VERSION ""

NS_ :

BS_:

BU_: VCU ACU Jetson Maxon Dynamics FSG_Datalogger RES

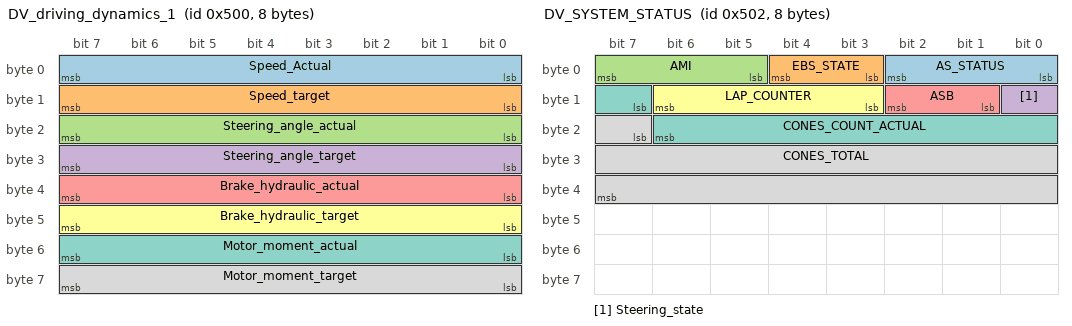
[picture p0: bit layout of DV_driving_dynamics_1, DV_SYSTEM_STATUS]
BO_ 1280 DV_driving_dynamics_1: 8 Dynamics
 SG_ Speed_Actual : 0|8@1+ (1,0) [0|0] "Km/h"  FSG_Datalogger
 SG_ Speed_target : 8|8@1+ (1,0) [0|0] "Km/h"  FSG_Datalogger
 SG_ Steering_angle_actual : 16|8@1- (1,0) [0|0] "°"  FSG_Datalogger
 SG_ Steering_angle_target : 24|8@1- (1,0) [0|0] "°"  FSG_Datalogger
 SG_ Brake_hydraulic_actual : 32|8@1+ (1,0) [0|0] "%"  FSG_Datalogger,ACU
 SG_ Brake_hydraulic_target : 40|8@1+ (1,0) [0|0] "%"  FSG_Datalogger
 SG_ Motor_moment_actual : 48|8@1- (1,0) [0|0] "%"  FSG_Datalogger
 SG_ Motor_moment_target : 56|8@1- (1,0) [0|0] "%"  FSG_Datalogger

BO_ 1282 DV_SYSTEM_STATUS: 8 ACU
 SG_ AS_STATUS : 0|3@1+ (1,0) [0|0] ""  FSG_Datalogger
 SG_ EBS_STATE : 3|2@1+ (1,0) [0|0] ""  FSG_Datalogger
 SG_ AMI : 5|3@1+ (1,0) [0|0] ""  FSG_Datalogger
 SG_ Steering_state : 8|1@1+ (1,0) [0|0] ""  FSG_Datalogger
 SG_ ASB : 9|2@1+ (1,0) [0|0] ""  FSG_Datalogger
 SG_ LAP_COUNTER : 11|4@1+ (1,0) [0|0] ""  FSG_Datalogger
 SG_ CONES_COUNT_ACTUAL : 15|8@1+ (1,0) [0|0] ""  FSG_Datalogger
 SG_ CONES_TOTAL : 23|17@1+ (1,0) [0|0] ""  FSG_Datalogger

BO_ 401 RES: 8 RES
 SG_ RES : 0|8@1+ (1,0) [0|0] ""  ACU,Jetson

BO_ 81 ACU_SIGNALS: 2 ACU
 SG_ MS : 0|8@1+ (1,0) [0|0] ""  Jetson
 SG_ IGN : 8|8@1+ (1,0) [0|0] ""  VCU

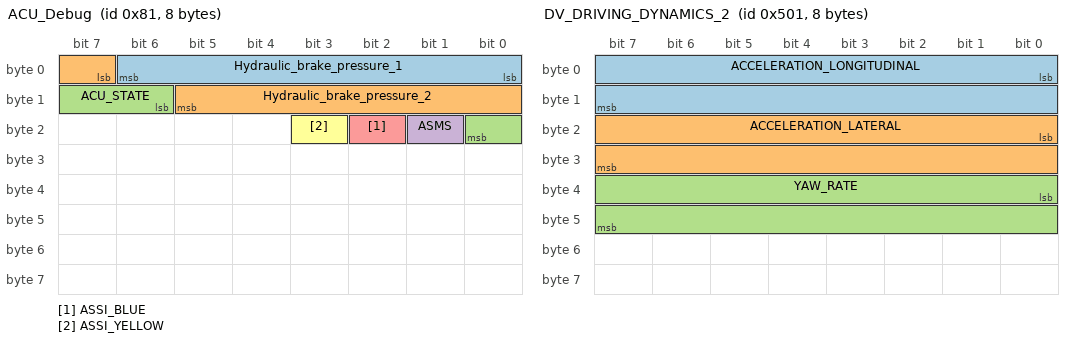
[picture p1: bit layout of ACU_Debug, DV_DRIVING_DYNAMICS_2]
BO_ 129 ACU_Debug: 8 ACU
 SG_ Hydraulic_brake_pressure_1 : 0|7@1+ (0.1,0) [0|10.5] "BAR" Vector__XXX
 SG_ Hydraulic_brake_pressure_2 : 7|7@1+ (0.1,0) [0|10] "BAR" Vector__XXX
 SG_ ACU_STATE : 14|3@1+ (1,0) [0|0] "" Vector__XXX
 SG_ ASMS : 17|1@1+ (1,0) [0|0] "" Vector__XXX
 SG_ ASSI_BLUE : 18|1@1+ (1,0) [0|0] "" Vector__XXX
 SG_ ASSI_YELLOW : 19|1@1+ (1,0) [0|0] "" Vector__XXX

BO_ 1281 DV_DRIVING_DYNAMICS_2: 8 Jetson
 SG_ ACCELERATION_LONGITUDINAL : 0|16@1- (1,0) [0|0] "m/s^2"  FSG_Datalogger
 SG_ ACCELERATION_LATERAL : 16|16@1- (1,0) [0|0] "m/s^2"  FSG_Datalogger
 SG_ YAW_RATE : 32|16@1- (1,0) [0|0] "m/s
2"  FSG_Datalogger

VAL_ 1282 AS_STATUS 1 "OFF" 2 "READY" 3 "DRIVING" 4 "EMERGENCY" 5 "FINISHED" ;
VAL_ 1282 EBS_STATE 1 "DEACTIVATED" 2 "INITIAL_CHECKUP_PASSED" 3 "ACTIVATED" ;
VAL_ 1282 AMI 1 "ACCELERATION" 2 "SKIDPAD" 3 "TRACKDRIVE" 4 "BRAKETEST" 5 "INSPECTION" 6 "AUTOCROSS" ;
VAL_ 1282 ASB 1 "Deactivated" 2 "Engaged" 3 "Initial_checkup" ;
VAL_ 401 RES 5 "GO_SIGNAL_1" 7 "GO_SIGNAL_2" 0 "EMERGENCY" ;
VAL_ 81 MS 1 "Manual" 2 "Acceleration" 3 "Skidpad" 4 "Trackdrive" 5 "BrakeTest" 6 "Autocross" ;
VAL_ 81 IGN 0 "OFF" 1 "ON" ;
VAL_ 129 ACU_STATE 1 "Mission_Select" 2 "Initial_sequence" 3 "Manual_mode" 4 "Autonomous_mode" 5 "Emergency" 6 "Reset" ;
VAL_ 129 ASMS 0 "OFF" 1 "ON" ;
VAL_ 129 ASSI_BLUE 0 "OFF" 1 "ON" ;
VAL_ 129 ASSI_YELLOW 0 "OFF" 1 "ON" ;
